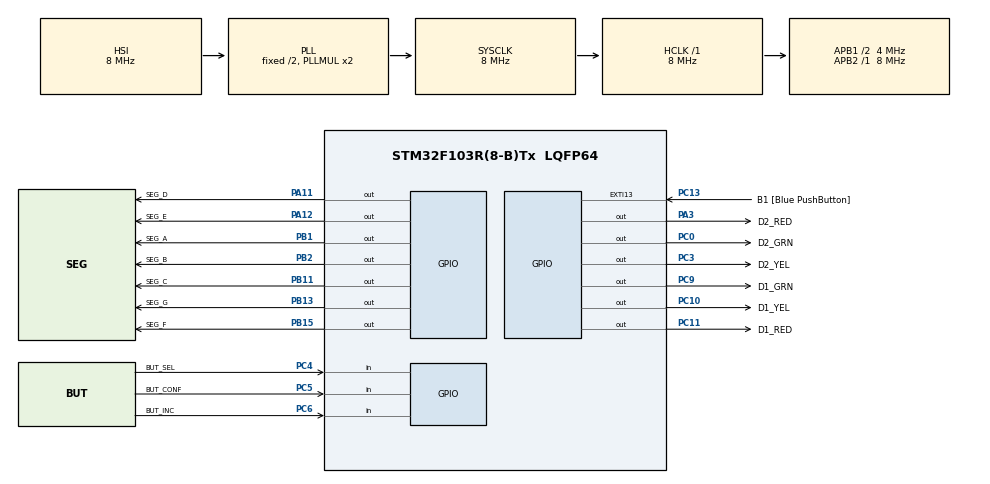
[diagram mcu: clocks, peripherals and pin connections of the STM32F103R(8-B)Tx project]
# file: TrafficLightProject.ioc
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Mcu.Family=STM32F1
Mcu.Name=STM32F103R(8-B)Tx
Mcu.Package=LQFP64
NVIC.PriorityGroup=NVIC_PRIORITYGROUP_4
NVIC.TIM2_IRQn=true\:0\:0\:false\:false\:true\:true\:true\:true
PA11.GPIO_Label=SEG_D
PA11.Signal=GPIO_Output
PA12.GPIO_Label=SEG_E
PA12.Signal=GPIO_Output
PA13.Mode=Serial_Wire
PA13.Signal=SYS_JTMS-SWDIO
PA14.GPIO_Label=TCK
PA14.Mode=Serial_Wire
PA14.Signal=SYS_JTCK-SWCLK
PA3.GPIO_Label=D2_RED
PA3.Signal=GPIO_Output
PB1.GPIO_Label=SEG_A
PB1.Signal=GPIO_Output
PB11.GPIO_Label=SEG_C
PB11.Signal=GPIO_Output
PB13.GPIO_Label=SEG_G
PB13.Signal=GPIO_Output
PB15.GPIO_Label=SEG_F
PB15.Signal=GPIO_Output
PB2.GPIO_Label=SEG_B
PB2.Signal=GPIO_Output
PB3.GPIO_Label=SWO
PB3.Signal=SYS_JTDO-TRACESWO
PC0.GPIO_Label=D2_GRN
PC0.Signal=GPIO_Output
PC10.GPIO_Label=D1_YEL
PC10.Signal=GPIO_Output
PC11.GPIO_Label=D1_RED
PC11.Signal=GPIO_Output
PC13-TAMPER-RTC.GPIO_Label=B1 [Blue PushButton]
PC13-TAMPER-RTC.GPIO_PuPd=GPIO_NOPULL
PC13-TAMPER-RTC.Signal=GPXTI13
PC14-OSC32_IN.Mode=LSE-External-Oscillator
PC14-OSC32_IN.Signal=RCC_OSC32_IN
PC15-OSC32_OUT.Mode=LSE-External-Oscillator
PC15-OSC32_OUT.Signal=RCC_OSC32_OUT
PC3.GPIO_Label=D2_YEL
PC3.Signal=GPIO_Output
PC4.GPIO_Label=BUT_SEL
PC4.Signal=GPIO_Input
PC5.GPIO_Label=BUT_CONF
PC5.Signal=GPIO_Input
PC6.GPIO_Label=BUT_INC
PC6.Signal=GPIO_Input
PC9.GPIO_Label=D1_GRN
PC9.Signal=GPIO_Output
PD0-OSC_IN.Mode=HSE-External-Clock-Source
PD0-OSC_IN.Signal=RCC_OSC_IN
PD1-OSC_OUT.Mode=HSE-External-Clock-Source
PD1-OSC_OUT.Signal=RCC_OSC_OUT
ProjectManager.HeapSize=0x200
ProjectManager.StackSize=0x400
ProjectManager.TargetToolchain=STM32CubeIDE
RCC.AHBFreq_Value=8000000
RCC.APB1CLKDivider=RCC_HCLK_DIV2
RCC.APB1Freq_Value=4000000
RCC.APB1TimFreq_Value=8000000
RCC.APB2Freq_Value=8000000
RCC.APB2TimFreq_Value=8000000
RCC.HCLKFreq_Value=8000000
RCC.RTCClockSelection=RCC_RTCCLKSOURCE_LSE
RCC.SYSCLKFreq_VALUE=8000000
RCC.SYSCLKSource=RCC_SYSCLKSOURCE_PLLCLK
RCC.USBFreq_Value=8000000
TIM2.Period=9
TIM2.Prescaler=7999
VP_TIM2_VS_ClockSourceINT.Mode=Internal
board=NUCLEO-F103RB

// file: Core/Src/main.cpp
/* USER CODE BEGIN Header */
/**
 ******************************************************************************
 * @file           : main.c
 * @brief          : Main program body
 ******************************************************************************
 * @attention
 *
 * Copyright (c) 2023 STMicroelectronics.
 * All rights reserved.
 *
 * This software is licensed under terms that can be found in the LICENSE file
 * in the root directory of this software component.
 * If no LICENSE file comes with this software, it is provided AS-IS.
 *
 ******************************************************************************
 */
/* USER CODE END Header */
#include "main.h"
#include "global.h"

/* USER CODE BEGIN PV */
TIM_HandleTypeDef htim2;

/* USER CODE END PV */

void SystemClock_Config(void);
static void MX_GPIO_Init(void);
static void MX_TIM2_Init(void);
void HAL_TIM_PeriodElapsedCallback(TIM_HandleTypeDef* htim);

/* USER CODE BEGIN 0 */

/*
 * Main controller
 * Controls the whole program
 */
extern Controller g_Controller;

/* USER CODE END 0 */

int main(void)
{

    /* MCU Configuration--------------------------------------------------------*/

    /* Reset of all peripherals, Initializes the Flash interface and the Systick. */
    HAL_Init();

    /* Configure the system clock */
    SystemClock_Config();

    /* Initialize all configured peripherals */
    MX_GPIO_Init();
    MX_TIM2_Init();
    HAL_TIM_Base_Start_IT(&htim2);

    /* Infinite loop */
    /* USER CODE BEGIN WHILE */
    while (1) {
        g_Controller.Run();
        /* USER CODE END WHILE */

    }
}

/* USER CODE BEGIN 4 */
void HAL_TIM_PeriodElapsedCallback(TIM_HandleTypeDef* htim)
{
    /* Timers */
    g_TimerGlobal.Breath();
    g_TimerSecond.Breath();

    /* Buttons */
    g_ButtonSelect.Listen();
    g_ButtonIncrement.Listen();
    g_ButtonConfirm.Listen();
}
/* USER CODE END 4 */

void SystemClock_Config(void)
{
  RCC_OscInitTypeDef RCC_OscInitStruct = {0};
  RCC_ClkInitTypeDef RCC_ClkInitStruct = {0};

  /** Initializes the RCC Oscillators according to the specified parameters
  * in the RCC_OscInitTypeDef structure.
  */
  RCC_OscInitStruct.OscillatorType = RCC_OSCILLATORTYPE_HSI;
  RCC_OscInitStruct.HSIState = RCC_HSI_ON;
  RCC_OscInitStruct.HSICalibrationValue = RCC_HSICALIBRATION_DEFAULT;
  RCC_OscInitStruct.PLL.PLLState = RCC_PLL_ON;
  RCC_OscInitStruct.PLL.PLLSource = RCC_PLLSOURCE_HSI_DIV2;
  RCC_OscInitStruct.PLL.PLLMUL = RCC_PLL_MUL2;
  if (HAL_RCC_OscConfig(&RCC_OscInitStruct) != HAL_OK)
  {
    Error_Handler();
  }

  /** Initializes the CPU, AHB and APB buses clocks
  */
  RCC_ClkInitStruct.ClockType = RCC_CLOCKTYPE_HCLK|RCC_CLOCKTYPE_SYSCLK
                              |RCC_CLOCKTYPE_PCLK1|RCC_CLOCKTYPE_PCLK2;
  RCC_ClkInitStruct.SYSCLKSource = RCC_SYSCLKSOURCE_PLLCLK;
  RCC_ClkInitStruct.AHBCLKDivider = RCC_SYSCLK_DIV1;
  RCC_ClkInitStruct.APB1CLKDivider = RCC_HCLK_DIV2;
  RCC_ClkInitStruct.APB2CLKDivider = RCC_HCLK_DIV1;

  if (HAL_RCC_ClockConfig(&RCC_ClkInitStruct, FLASH_LATENCY_0) != HAL_OK)
  {
    Error_Handler();
  }
}

static void MX_TIM2_Init(void)
{

  TIM_ClockConfigTypeDef sClockSourceConfig = {0};
  TIM_MasterConfigTypeDef sMasterConfig = {0};

  htim2.Instance = TIM2;
  htim2.Init.Prescaler = 7999;
  htim2.Init.CounterMode = TIM_COUNTERMODE_UP;
  htim2.Init.Period = 9;
  htim2.Init.ClockDivision = TIM_CLOCKDIVISION_DIV1;
  htim2.Init.AutoReloadPreload = TIM_AUTORELOAD_PRELOAD_DISABLE;
  if (HAL_TIM_Base_Init(&htim2) != HAL_OK)
  {
    Error_Handler();
  }
  sClockSourceConfig.ClockSource = TIM_CLOCKSOURCE_INTERNAL;
  if (HAL_TIM_ConfigClockSource(&htim2, &sClockSourceConfig) != HAL_OK)
  {
    Error_Handler();
  }
  sMasterConfig.MasterOutputTrigger = TIM_TRGO_RESET;
  sMasterConfig.MasterSlaveMode = TIM_MASTERSLAVEMODE_DISABLE;
  if (HAL_TIMEx_MasterConfigSynchronization(&htim2, &sMasterConfig) != HAL_OK)
  {
    Error_Handler();
  }

}

static void MX_GPIO_Init(void)
{
  GPIO_InitTypeDef GPIO_InitStruct = {0};

  /* GPIO Ports Clock Enable */
  __HAL_RCC_GPIOC_CLK_ENABLE();
  __HAL_RCC_GPIOD_CLK_ENABLE();
  __HAL_RCC_GPIOA_CLK_ENABLE();
  __HAL_RCC_GPIOB_CLK_ENABLE();

  /*Configure GPIO pin Output Level */
  HAL_GPIO_WritePin(GPIOC, D2_GRN_Pin|D2_YEL_Pin|D1_GRN_Pin|D1_YEL_Pin
                          |D1_RED_Pin, GPIO_PIN_RESET);

  /*Configure GPIO pin Output Level */
  HAL_GPIO_WritePin(GPIOA, D2_RED_Pin|SEG_D_Pin|SEG_E_Pin, GPIO_PIN_RESET);

  /*Configure GPIO pin Output Level */
  HAL_GPIO_WritePin(GPIOB, SEG_A_Pin|SEG_B_Pin|SEG_C_Pin|SEG_G_Pin
                          |SEG_F_Pin, GPIO_PIN_RESET);

  /*Configure GPIO pin : B1_Pin */
  GPIO_InitStruct.Pin = B1_Pin;
  GPIO_InitStruct.Mode = GPIO_MODE_IT_RISING;
  GPIO_InitStruct.Pull = GPIO_NOPULL;
  HAL_GPIO_Init(B1_GPIO_Port, &GPIO_InitStruct);

  /*Configure GPIO pins : D2_GRN_Pin D2_YEL_Pin D1_GRN_Pin D1_YEL_Pin
                           D1_RED_Pin */
  GPIO_InitStruct.Pin = D2_GRN_Pin|D2_YEL_Pin|D1_GRN_Pin|D1_YEL_Pin
                          |D1_RED_Pin;
  GPIO_InitStruct.Mode = GPIO_MODE_OUTPUT_PP;
  GPIO_InitStruct.Pull = GPIO_NOPULL;
  GPIO_InitStruct.Speed = GPIO_SPEED_FREQ_LOW;
  HAL_GPIO_Init(GPIOC, &GPIO_InitStruct);

  /*Configure GPIO pins : D2_RED_Pin SEG_D_Pin SEG_E_Pin */
  GPIO_InitStruct.Pin = D2_RED_Pin|SEG_D_Pin|SEG_E_Pin;
  GPIO_InitStruct.Mode = GPIO_MODE_OUTPUT_PP;
  GPIO_InitStruct.Pull = GPIO_NOPULL;
  GPIO_InitStruct.Speed = GPIO_SPEED_FREQ_LOW;
  HAL_GPIO_Init(GPIOA, &GPIO_InitStruct);

  /*Configure GPIO pins : BUT_SEL_Pin BUT_CONF_Pin BUT_INC_Pin */
  GPIO_InitStruct.Pin = BUT_SEL_Pin|BUT_CONF_Pin|BUT_INC_Pin;
  GPIO_InitStruct.Mode = GPIO_MODE_INPUT;
  GPIO_InitStruct.Pull = GPIO_PULLUP;
  HAL_GPIO_Init(GPIOC, &GPIO_InitStruct);

  /*Configure GPIO pins : SEG_A_Pin SEG_B_Pin SEG_C_Pin SEG_G_Pin
                           SEG_F_Pin */
  GPIO_InitStruct.Pin = SEG_A_Pin|SEG_B_Pin|SEG_C_Pin|SEG_G_Pin
                          |SEG_F_Pin;
  GPIO_InitStruct.Mode = GPIO_MODE_OUTPUT_PP;
  GPIO_InitStruct.Pull = GPIO_NOPULL;
  GPIO_InitStruct.Speed = GPIO_SPEED_FREQ_LOW;
  HAL_GPIO_Init(GPIOB, &GPIO_InitStruct);

}

void Error_Handler(void)
{
  __disable_irq();
  while (1)
  {
  }
}
